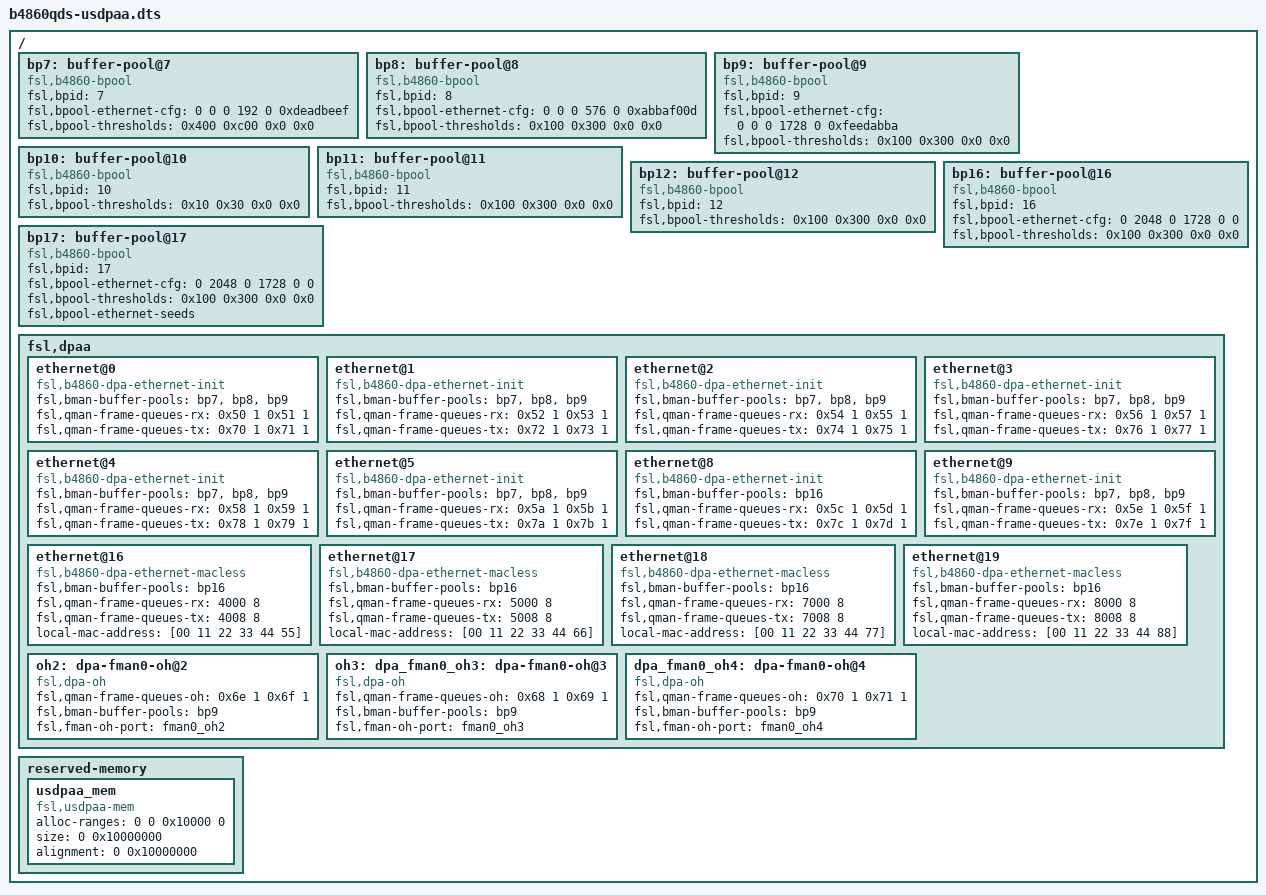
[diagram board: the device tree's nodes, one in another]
/*
 * B4860QDS Device Tree Source
 *
 * Copyright 2012 Freescale Semiconductor Inc.
 *
 * Redistribution and use in source and binary forms, with or without
 * modification, are permitted provided that the following conditions are met:
 *     * Redistributions of source code must retain the above copyright
 *       notice, this list of conditions and the following disclaimer.
 *     * Redistributions in binary form must reproduce the above copyright
 *       notice, this list of conditions and the following disclaimer in the
 *       documentation and/or other materials provided with the distribution.
 *     * Neither the name of Freescale Semiconductor nor the
 *       names of its contributors may be used to endorse or promote products
 *       derived from this software without specific prior written permission.
 *
 *
 * ALTERNATIVELY, this software may be distributed under the terms of the
 * GNU General Public License ("GPL") as published by the Free Software
 * Foundation, either version 2 of that License or (at your option) any
 * later version.
 *
 * THIS SOFTWARE IS PROVIDED BY Freescale Semiconductor ``AS IS'' AND ANY
 * EXPRESS OR IMPLIED WARRANTIES, INCLUDING, BUT NOT LIMITED TO, THE IMPLIED
 * WARRANTIES OF MERCHANTABILITY AND FITNESS FOR A PARTICULAR PURPOSE ARE
 * DISCLAIMED. IN NO EVENT SHALL Freescale Semiconductor BE LIABLE FOR ANY
 * DIRECT, INDIRECT, INCIDENTAL, SPECIAL, EXEMPLARY, OR CONSEQUENTIAL DAMAGES
 * (INCLUDING, BUT NOT LIMITED TO, PROCUREMENT OF SUBSTITUTE GOODS OR SERVICES;
 * LOSS OF USE, DATA, OR PROFITS; OR BUSINESS INTERRUPTION) HOWEVER CAUSED AND
 * ON ANY THEORY OF LIABILITY, WHETHER IN CONTRACT, STRICT LIABILITY, OR TORT
 * (INCLUDING NEGLIGENCE OR OTHERWISE) ARISING IN ANY WAY OUT OF THE USE OF THIS
 * SOFTWARE, EVEN IF ADVISED OF THE POSSIBILITY OF SUCH DAMAGE.
 */

/include/ "b4860qds.dts"

/ {
	/* NB: "bpool-ethernet-seeds" is not set to avoid buffer seeding,
	 * because apps seed these pools with buffers allocated at
	 * run-time.
	 * HOWEVER, the kernel driver requires the buffer-size so
	 * "fsl,bpool-ethernet-cfg" is set. It also mis-interprets
	 * things if the base-address is zero (hence the 0xdeadbeef
	 * values).
	 */
	bp7: buffer-pool@7 {
		compatible = "fsl,b4860-bpool", "fsl,bpool";
		fsl,bpid = <7>;
		fsl,bpool-ethernet-cfg = <0 0 0 192 0 0xdeadbeef>;
		fsl,bpool-thresholds = <0x400 0xc00 0x0 0x0>;
	};
	bp8: buffer-pool@8 {
		compatible = "fsl,b4860-bpool", "fsl,bpool";
		fsl,bpid = <8>;
		fsl,bpool-ethernet-cfg = <0 0 0 576 0 0xabbaf00d>;
		fsl,bpool-thresholds = <0x100 0x300 0x0 0x0>;
	};
	bp9: buffer-pool@9 {
		compatible = "fsl,b4860-bpool", "fsl,bpool";
		fsl,bpid = <9>;
		fsl,bpool-ethernet-cfg = <0 0 0 1728 0 0xfeedabba>;
		fsl,bpool-thresholds = <0x100 0x300 0x0 0x0>;
	};

	bp10: buffer-pool@10 {
		compatible = "fsl,b4860-bpool", "fsl,bpool";
		fsl,bpid = <10>;
		fsl,bpool-thresholds = <0x10 0x30 0x0 0x0>;
	};
	bp11: buffer-pool@11 {
		compatible = "fsl,b4860-bpool", "fsl,bpool";
		fsl,bpid = <11>;
		fsl,bpool-thresholds = <0x100 0x300 0x0 0x0>;
	};
	bp12: buffer-pool@12 {
		compatible = "fsl,b4860-bpool", "fsl,bpool";
		fsl,bpid = <12>;
		fsl,bpool-thresholds = <0x100 0x300 0x0 0x0>;
	};

	bp16: buffer-pool@16 {
			compatible = "fsl,b4860-bpool", "fsl,bpool";
			fsl,bpid = <16>;
			fsl,bpool-ethernet-cfg = <0 2048 0 1728 0 0>;
			fsl,bpool-thresholds = <0x100 0x300 0x0 0x0>;
	};

	bp17: buffer-pool@17 {
			compatible = "fsl,b4860-bpool", "fsl,bpool";
			fsl,bpid = <17>;
			fsl,bpool-ethernet-cfg = <0 2048 0 1728 0 0>;
			fsl,bpool-thresholds = <0x100 0x300 0x0 0x0>;
			fsl,bpool-ethernet-seeds;
	};


	fsl,dpaa {
		ethernet@0 {
			compatible = "fsl,b4860-dpa-ethernet-init", "fsl,dpa-ethernet-init";
			fsl,bman-buffer-pools = <&bp7 &bp8 &bp9>;
			fsl,qman-frame-queues-rx = <0x50 1 0x51 1>;
			fsl,qman-frame-queues-tx = <0x70 1 0x71 1>;
		};
		ethernet@1 {
			compatible = "fsl,b4860-dpa-ethernet-init", "fsl,dpa-ethernet-init";
			fsl,bman-buffer-pools = <&bp7 &bp8 &bp9>;
			fsl,qman-frame-queues-rx = <0x52 1 0x53 1>;
			fsl,qman-frame-queues-tx = <0x72 1 0x73 1>;
		};
		ethernet@2 {
			compatible = "fsl,b4860-dpa-ethernet-init", "fsl,dpa-ethernet-init";
			fsl,bman-buffer-pools = <&bp7 &bp8 &bp9>;
			fsl,qman-frame-queues-rx = <0x54 1 0x55 1>;
			fsl,qman-frame-queues-tx = <0x74 1 0x75 1>;
		};
		ethernet@3 {
			compatible = "fsl,b4860-dpa-ethernet-init", "fsl,dpa-ethernet-init";
			fsl,bman-buffer-pools = <&bp7 &bp8 &bp9>;
			fsl,qman-frame-queues-rx = <0x56 1 0x57 1>;
			fsl,qman-frame-queues-tx = <0x76 1 0x77 1>;
		};
		ethernet@4 {
			compatible = "fsl,b4860-dpa-ethernet-init", "fsl,dpa-ethernet-init";
			fsl,bman-buffer-pools = <&bp7 &bp8 &bp9>;
			fsl,qman-frame-queues-rx = <0x58 1 0x59 1>;
			fsl,qman-frame-queues-tx = <0x78 1 0x79 1>;
		};
		ethernet@5 {
			compatible = "fsl,b4860-dpa-ethernet-init", "fsl,dpa-ethernet-init";
			fsl,bman-buffer-pools = <&bp7 &bp8 &bp9>;
			fsl,qman-frame-queues-rx = <0x5a 1 0x5b 1>;
			fsl,qman-frame-queues-tx = <0x7a 1 0x7b 1>;
		};
		ethernet@8 {
			compatible = "fsl,b4860-dpa-ethernet-init", "fsl,dpa-ethernet-init";
			fsl,bman-buffer-pools = <&bp16>;
			fsl,qman-frame-queues-rx = <0x5c 1 0x5d 1>;
			fsl,qman-frame-queues-tx = <0x7c 1 0x7d 1>;
		};
		ethernet@9 {
			compatible = "fsl,b4860-dpa-ethernet-init", "fsl,dpa-ethernet-init";
			fsl,bman-buffer-pools = <&bp7 &bp8 &bp9>;
			fsl,qman-frame-queues-rx = <0x5e 1 0x5f 1>;
			fsl,qman-frame-queues-tx = <0x7e 1 0x7f 1>;
		};

	       /* ethernet@16 declared as MAC-less interface with no "fsl,fman-mac" property.
                 * USDPAA will seed buffers to this buffer pool and initialize 8 TX Frame
                 * queues. The ethernet driver will initialize 8 RX default Frame queues.
                 * On receiving frame at this interface, the ethernet driver will do
                 * kmap_atomic/kunmap_atomic for that frame. */
               ethernet@16 {
                        compatible = "fsl,b4860-dpa-ethernet-macless", "fsl,dpa-ethernet-macless";
                        fsl,bman-buffer-pools = <&bp16>;
                        fsl,qman-frame-queues-rx = <4000 8>;
                        fsl,qman-frame-queues-tx = <4008 8>;
                        local-mac-address = [00 11 22 33 44 55];
                };
		ethernet@17 {
			compatible = "fsl,b4860-dpa-ethernet-macless", "fsl,dpa-ethernet-macless";
			fsl,bman-buffer-pools = <&bp16>;
			fsl,qman-frame-queues-rx = <5000 8>;
			fsl,qman-frame-queues-tx = <5008 8>;
			local-mac-address = [00 11 22 33 44 66];
		};
		ethernet@18 {
			compatible = "fsl,b4860-dpa-ethernet-macless", "fsl,dpa-ethernet-macless";
			fsl,bman-buffer-pools = <&bp16>;
			fsl,qman-frame-queues-rx = <7000 8>;
			fsl,qman-frame-queues-tx = <7008 8>;
			local-mac-address = [00 11 22 33 44 77];
		};
		ethernet@19 {
			compatible = "fsl,b4860-dpa-ethernet-macless", "fsl,dpa-ethernet-macless";
			fsl,bman-buffer-pools = <&bp16>;
			fsl,qman-frame-queues-rx = <8000 8>;
			fsl,qman-frame-queues-tx = <8008 8>;
			local-mac-address = [00 11 22 33 44 88];
		};

		oh2: dpa-fman0-oh@2 {
			compatible = "fsl,dpa-oh";
			/* Define frame queues for the OH port*/
			/* <OH Rx error, OH Rx default> */
			fsl,qman-frame-queues-oh = <0x6e 1 0x6f 1>;
			fsl,bman-buffer-pools = <&bp9>;
			fsl,fman-oh-port = <&fman0_oh2>;
		};
		oh3: dpa_fman0_oh3: dpa-fman0-oh@3 {
			compatible = "fsl,dpa-oh";
			fsl,qman-frame-queues-oh = <0x68 1 0x69 1>;
			fsl,bman-buffer-pools = <&bp9>;
			fsl,fman-oh-port = <&fman0_oh3>;
		};
		dpa_fman0_oh4: dpa-fman0-oh@4 {
			compatible = "fsl,dpa-oh";
			fsl,qman-frame-queues-oh = <0x70 1 0x71 1>;
			fsl,bman-buffer-pools = <&bp9>;
			fsl,fman-oh-port = <&fman0_oh4>;
		};

	};
	reserved-memory {
		#address-cells = <2>;
		#size-cells = <2>;
		ranges;

		usdpaa_mem: usdpaa_mem {
			compatible = "fsl,usdpaa-mem";
			alloc-ranges = <0 0 0x10000 0>;
			size = <0 0x10000000>;
			alignment = <0 0x10000000>;
		};
	};
};
